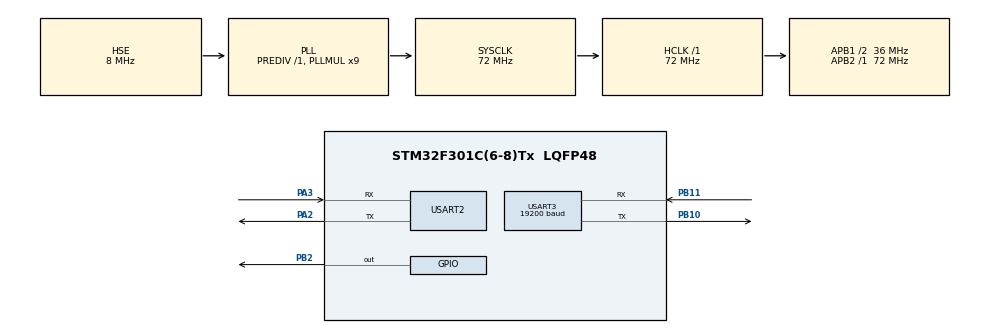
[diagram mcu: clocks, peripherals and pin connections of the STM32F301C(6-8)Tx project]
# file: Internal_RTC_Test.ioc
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Mcu.Family=STM32F3
Mcu.Name=STM32F301C(6-8)Tx
Mcu.Package=LQFP48
NVIC.PriorityGroup=NVIC_PRIORITYGROUP_4
PA2.Mode=Asynchronous
PA2.Signal=USART2_TX
PA3.Mode=Asynchronous
PA3.Signal=USART2_RX
PB10.Mode=Asynchronous
PB10.Signal=USART3_TX
PB11.Mode=Asynchronous
PB11.Signal=USART3_RX
PB2.Signal=GPIO_Output
PC14\ -\ OSC32_IN.Mode=LSE-External-Oscillator
PC14\ -\ OSC32_IN.Signal=RCC_OSC32_IN
PC15\ -\ OSC32_OUT.Mode=LSE-External-Oscillator
PC15\ -\ OSC32_OUT.Signal=RCC_OSC32_OUT
PF0-OSC_IN.Mode=HSE-External-Oscillator
PF0-OSC_IN.Signal=RCC_OSC_IN
PF1-OSC_OUT.Mode=HSE-External-Oscillator
PF1-OSC_OUT.Signal=RCC_OSC_OUT
ProjectManager.HeapSize=0x200
ProjectManager.StackSize=0x400
ProjectManager.TargetToolchain=STM32CubeIDE
RCC.AHBFreq_Value=72000000
RCC.APB1CLKDivider=RCC_HCLK_DIV2
RCC.APB1Freq_Value=36000000
RCC.APB1TimFreq_Value=72000000
RCC.APB2Freq_Value=72000000
RCC.APB2TimFreq_Value=72000000
RCC.CortexFreq_Value=72000000
RCC.HCLKFreq_Value=72000000
RCC.HSE_VALUE=8000000
RCC.HSI_VALUE=8000000
RCC.PLLMUL=RCC_PLL_MUL9
RCC.PLLSourceVirtual=RCC_PLLSOURCE_HSE
RCC.RTCClockSelection=RCC_RTCCLKSOURCE_LSE
RCC.SYSCLKFreq_VALUE=72000000
RCC.SYSCLKSourceVirtual=RCC_SYSCLKSOURCE_PLLCLK
RTC.Date=15
RTC.Hours=12
RTC.Minutes=15
RTC.Seconds=20
RTC.WeekDay=RTC_WEEKDAY_FRIDAY
RTC.Year=20
USART2.VirtualMode-Asynchronous=VM_ASYNC
USART3.BaudRate=19200
USART3.VirtualMode-Asynchronous=VM_ASYNC
VP_RTC_VS_RTC_Activate.Mode=RTC_Enabled
VP_RTC_VS_RTC_Calendar.Mode=RTC_Calendar
board=custom

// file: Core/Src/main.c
/* USER CODE BEGIN Header */
/**
  ******************************************************************************
  * @file           : main.c
  * @brief          : Main program body
  ******************************************************************************
  * @attention
  *
  * <h2><center>&copy; Copyright (c) 2021 STMicroelectronics.
  * All rights reserved.</center></h2>
  *
  * This software component is licensed by ST under BSD 3-Clause license,
  * the "License"; You may not use this file except in compliance with the
  * License. You may obtain a copy of the License at:
  *                        opensource.org/licenses/BSD-3-Clause
  *
  ******************************************************************************
  */
/* USER CODE END Header */
#include "main.h"

RTC_HandleTypeDef hrtc;

UART_HandleTypeDef huart2;
UART_HandleTypeDef huart3;

void SystemClock_Config(void);
static void MX_GPIO_Init(void);
static void MX_RTC_Init(void);
static void MX_USART3_UART_Init(void);
static void MX_USART2_UART_Init(void);
/* USER CODE BEGIN PFP */
RTC_TimeTypeDef sTime = {0};
 RTC_DateTypeDef sDate = {0};
 uint8_t  Time[15],Date[15] ;

/* USER CODE END PFP */

int main(void)
{

  /* MCU Configuration--------------------------------------------------------*/

  /* Reset of all peripherals, Initializes the Flash interface and the Systick. */
  HAL_Init();

  /* Configure the system clock */
  SystemClock_Config();

  /* Initialize all configured peripherals */
  MX_GPIO_Init();
  MX_RTC_Init();
  MX_USART3_UART_Init();
  MX_USART2_UART_Init();
  /* USER CODE BEGIN 2 */

   HAL_GPIO_WritePin(GPIOB, GPIO_PIN_2, 0);
  /* USER CODE END 2 */

  /* Infinite loop */
  /* USER CODE BEGIN WHILE */
  while (1)
  {
	  HAL_RTC_GetTime(&hrtc, &sTime, RTC_FORMAT_BIN);
	 HAL_RTC_GetDate(&hrtc, &sDate, RTC_FORMAT_BIN);
	 sprintf(Time,"TIME  %02d:%02d",sTime.Hours,sTime.Minutes);
	 sprintf(Date,"DATE  %02d/%02d/%02d",sDate.Date,sDate.Month,sDate.Year);

	 HAL_UART_Transmit(&huart2, Time, 11, 10);
     HAL_UART_Transmit(&huart2, Date, 14, 10);
     HAL_UART_Transmit(&huart2, "\r\n", 4, 10);

    /* USER CODE END WHILE */

  }
}

void SystemClock_Config(void)
{
  RCC_OscInitTypeDef RCC_OscInitStruct = {0};
  RCC_ClkInitTypeDef RCC_ClkInitStruct = {0};
  RCC_PeriphCLKInitTypeDef PeriphClkInit = {0};

  /** Configure LSE Drive Capability
  */
  HAL_PWR_EnableBkUpAccess();
  __HAL_RCC_LSEDRIVE_CONFIG(RCC_LSEDRIVE_LOW);
  /** Initializes the RCC Oscillators according to the specified parameters
  * in the RCC_OscInitTypeDef structure.
  */
  RCC_OscInitStruct.OscillatorType = RCC_OSCILLATORTYPE_HSE|RCC_OSCILLATORTYPE_LSE;
  RCC_OscInitStruct.HSEState = RCC_HSE_ON;
  RCC_OscInitStruct.HSEPredivValue = RCC_HSE_PREDIV_DIV1;
  RCC_OscInitStruct.LSEState = RCC_LSE_ON;
  RCC_OscInitStruct.HSIState = RCC_HSI_ON;
  RCC_OscInitStruct.PLL.PLLState = RCC_PLL_ON;
  RCC_OscInitStruct.PLL.PLLSource = RCC_PLLSOURCE_HSE;
  RCC_OscInitStruct.PLL.PLLMUL = RCC_PLL_MUL9;
  if (HAL_RCC_OscConfig(&RCC_OscInitStruct) != HAL_OK)
  {
    Error_Handler();
  }
  /** Initializes the CPU, AHB and APB buses clocks
  */
  RCC_ClkInitStruct.ClockType = RCC_CLOCKTYPE_HCLK|RCC_CLOCKTYPE_SYSCLK
                              |RCC_CLOCKTYPE_PCLK1|RCC_CLOCKTYPE_PCLK2;
  RCC_ClkInitStruct.SYSCLKSource = RCC_SYSCLKSOURCE_PLLCLK;
  RCC_ClkInitStruct.AHBCLKDivider = RCC_SYSCLK_DIV1;
  RCC_ClkInitStruct.APB1CLKDivider = RCC_HCLK_DIV2;
  RCC_ClkInitStruct.APB2CLKDivider = RCC_HCLK_DIV1;

  if (HAL_RCC_ClockConfig(&RCC_ClkInitStruct, FLASH_LATENCY_2) != HAL_OK)
  {
    Error_Handler();
  }
  PeriphClkInit.PeriphClockSelection = RCC_PERIPHCLK_RTC;
  PeriphClkInit.RTCClockSelection = RCC_RTCCLKSOURCE_LSE;
  if (HAL_RCCEx_PeriphCLKConfig(&PeriphClkInit) != HAL_OK)
  {
    Error_Handler();
  }
}

static void MX_RTC_Init(void)
{

  RTC_TimeTypeDef sTime = {0};
  RTC_DateTypeDef sDate = {0};

  /** Initialize RTC Only
  */
  hrtc.Instance = RTC;
  hrtc.Init.HourFormat = RTC_HOURFORMAT_24;
  hrtc.Init.AsynchPrediv = 127;
  hrtc.Init.SynchPrediv = 255;
  hrtc.Init.OutPut = RTC_OUTPUT_DISABLE;
  hrtc.Init.OutPutPolarity = RTC_OUTPUT_POLARITY_HIGH;
  hrtc.Init.OutPutType = RTC_OUTPUT_TYPE_OPENDRAIN;
  if (HAL_RTC_Init(&hrtc) != HAL_OK)
  {
    Error_Handler();
  }

  /** Initialize RTC and set the Time and Date
  */
  sTime.Hours = 0x12;
  sTime.Minutes = 0x15;
  sTime.Seconds = 0x20;
  sTime.DayLightSaving = RTC_DAYLIGHTSAVING_NONE;
  sTime.StoreOperation = RTC_STOREOPERATION_RESET;
  if (HAL_RTC_SetTime(&hrtc, &sTime, RTC_FORMAT_BCD) != HAL_OK)
  {
    Error_Handler();
  }
  sDate.WeekDay = RTC_WEEKDAY_FRIDAY;
  sDate.Month = RTC_MONTH_JANUARY;
  sDate.Date = 0x15;
  sDate.Year = 0x20;

  if (HAL_RTC_SetDate(&hrtc, &sDate, RTC_FORMAT_BCD) != HAL_OK)
  {
    Error_Handler();
  }

}

static void MX_USART2_UART_Init(void)
{

  huart2.Instance = USART2;
  huart2.Init.BaudRate = 38400;
  huart2.Init.WordLength = UART_WORDLENGTH_8B;
  huart2.Init.StopBits = UART_STOPBITS_1;
  huart2.Init.Parity = UART_PARITY_NONE;
  huart2.Init.Mode = UART_MODE_TX_RX;
  huart2.Init.HwFlowCtl = UART_HWCONTROL_NONE;
  huart2.Init.OverSampling = UART_OVERSAMPLING_16;
  huart2.Init.OneBitSampling = UART_ONE_BIT_SAMPLE_DISABLE;
  huart2.AdvancedInit.AdvFeatureInit = UART_ADVFEATURE_NO_INIT;
  if (HAL_UART_Init(&huart2) != HAL_OK)
  {
    Error_Handler();
  }

}

static void MX_USART3_UART_Init(void)
{

  huart3.Instance = USART3;
  huart3.Init.BaudRate = 19200;
  huart3.Init.WordLength = UART_WORDLENGTH_8B;
  huart3.Init.StopBits = UART_STOPBITS_1;
  huart3.Init.Parity = UART_PARITY_NONE;
  huart3.Init.Mode = UART_MODE_TX_RX;
  huart3.Init.HwFlowCtl = UART_HWCONTROL_NONE;
  huart3.Init.OverSampling = UART_OVERSAMPLING_16;
  huart3.Init.OneBitSampling = UART_ONE_BIT_SAMPLE_DISABLE;
  huart3.AdvancedInit.AdvFeatureInit = UART_ADVFEATURE_NO_INIT;
  if (HAL_UART_Init(&huart3) != HAL_OK)
  {
    Error_Handler();
  }

}

static void MX_GPIO_Init(void)
{
  GPIO_InitTypeDef GPIO_InitStruct = {0};

  /* GPIO Ports Clock Enable */
  __HAL_RCC_GPIOC_CLK_ENABLE();
  __HAL_RCC_GPIOF_CLK_ENABLE();
  __HAL_RCC_GPIOA_CLK_ENABLE();
  __HAL_RCC_GPIOB_CLK_ENABLE();

  /*Configure GPIO pin Output Level */
  HAL_GPIO_WritePin(GPIOB, GPIO_PIN_2, GPIO_PIN_RESET);

  /*Configure GPIO pin : PB2 */
  GPIO_InitStruct.Pin = GPIO_PIN_2;
  GPIO_InitStruct.Mode = GPIO_MODE_OUTPUT_PP;
  GPIO_InitStruct.Pull = GPIO_NOPULL;
  GPIO_InitStruct.Speed = GPIO_SPEED_FREQ_LOW;
  HAL_GPIO_Init(GPIOB, &GPIO_InitStruct);

}

void Error_Handler(void)
{
}

/************************ (C) COPYRIGHT STMicroelectronics *****END OF FILE****/
